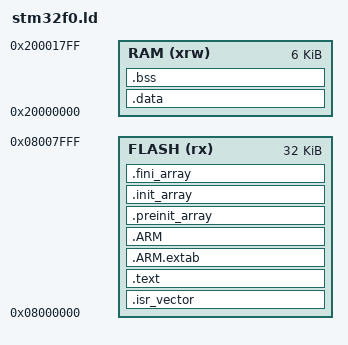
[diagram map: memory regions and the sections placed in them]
/* Linker script for STM32F042F6Px Device with 32KByte FLASH, 6KByte RAM
   This file is taken from lib/cmsis-stm32f0/source/STM32F042F6Px_FLASH.ld
*/

ENTRY(Reset_Handler)

MEMORY
{
  FLASH (rx) : ORIGIN = 0x08000000, LENGTH = 32K
  RAM  (xrw) : ORIGIN = 0x20000000, LENGTH = 6K
}

/* highest address of the user mode stack */
_estack = 0x20001800;

SECTIONS
{
    /* Interrupt vector table */
    .isr_vector :
    {
        . = ALIGN(4);
        KEEP(*(.isr_vector))
        . = ALIGN(4);
    } >FLASH

    /* Program code and constant data */
    .text :
    {
        . = ALIGN(4);
        *(.text)
        *(.text*)
        *(.rodata)
        *(.rodata*)
        KEEP (*(.init))
        KEEP (*(.fini))
        . = ALIGN(4);
        _etext = .;
    } >FLASH

    /* Exception handling */
    .ARM.extab   : { *(.ARM.extab* .gnu.linkonce.armextab.*) } >FLASH
    .ARM : {
        __exidx_start = .;
        *(.ARM.exidx*)
        __exidx_end = .;
    } >FLASH

    /* Static constructor initialization (C++) */
    .preinit_array :
    {
        PROVIDE_HIDDEN (__preinit_array_start = .);
        KEEP (*(.preinit_array*))
        PROVIDE_HIDDEN (__preinit_array_end = .);
    } >FLASH
    .init_array :
    {
        PROVIDE_HIDDEN (__init_array_start = .);
        KEEP (*(SORT(.init_array.*)))
        KEEP (*(.init_array*))
        PROVIDE_HIDDEN (__init_array_end = .);
    } >FLASH
    .fini_array :
    {
        PROVIDE_HIDDEN (__fini_array_start = .);
        KEEP (*(SORT(.fini_array.*)))
        KEEP (*(.fini_array*))
        PROVIDE_HIDDEN (__fini_array_end = .);
    } >FLASH


    /* Initialized data, needs to be handled by startup code */
    _sidata = .;
    .data : AT (_sidata)
    {
        . = ALIGN(4);
        _sdata = . ;
        _data = . ;
        *(.data)
        *(.data*)
        *(.RAMtext)
        . = ALIGN(4);
        _edata = . ;
    } >RAM

    /* Uninitialized data */
    .bss (NOLOAD) :
    {
        . = ALIGN(4);
        _sbss = .;
        __bss_start__ = .;
        _bss = .;
        *(.bss)
        *(.bss*)
        *(COMMON)
        . = ALIGN(4);
        _ebss = .;
        __bss_end__ = _ebss;
    } >RAM

    /* Pointers to end of data for dynamic memory management */
    PROVIDE (end = _ebss);
    PROVIDE (_end = _ebss);

    /* Remove debugging from standard libraries */
    /DISCARD/ :
    {
        libc.a (*)
        libm.a (*)
        libgcc.a (*)
    }
}
